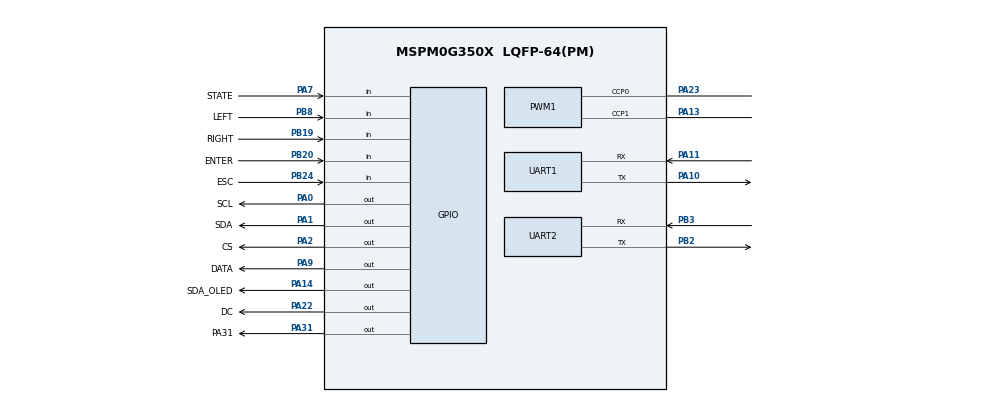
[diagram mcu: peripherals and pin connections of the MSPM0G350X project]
/**
 * @cliArgs --device "MSPM0G350X" --package "LQFP-64(PM)" --part "Default" --product "mspm0_sdk@1.30.00.03"
 * @versions {"tool":"1.19.0+3426"}
 */

/**
 * Import the modules used in this configuration.
 */
const GPIO    = scripting.addModule("/ti/driverlib/GPIO", {}, false);
const GPIO1   = GPIO.addInstance();
const GPIO2   = GPIO.addInstance();
const GPIO3   = GPIO.addInstance();
const GPIO4   = GPIO.addInstance();
const GPIO5   = GPIO.addInstance();
const GPIO6   = GPIO.addInstance();
const PWM     = scripting.addModule("/ti/driverlib/PWM", {}, false);
const PWM1    = PWM.addInstance();
const SYSCTL  = scripting.addModule("/ti/driverlib/SYSCTL");
const SYSTICK = scripting.addModule("/ti/driverlib/SYSTICK");
const UART    = scripting.addModule("/ti/driverlib/UART", {}, false);
const UART1   = UART.addInstance();
const UART2   = UART.addInstance();

/**
 * Write custom configuration values to the imported modules.
 */
GPIO1.$name                          = "GPIO";
GPIO1.port                           = "PORTA";
GPIO1.associatedPins.create(2);
GPIO1.associatedPins[0].$name        = "SCL";
GPIO1.associatedPins[0].initialValue = "SET";
GPIO1.associatedPins[0].ioStructure  = "OD";
GPIO1.associatedPins[0].assignedPin  = "0";
GPIO1.associatedPins[0].pin.$assign  = "PA0";
GPIO1.associatedPins[1].$name        = "SDA";
GPIO1.associatedPins[1].initialValue = "SET";
GPIO1.associatedPins[1].ioStructure  = "OD";
GPIO1.associatedPins[1].assignedPin  = "1";
GPIO1.associatedPins[1].pin.$assign  = "PA1";

const Board = scripting.addModule("/ti/driverlib/Board", {}, false);

GPIO2.$name                          = "GPIO_OLED";
GPIO2.port                           = "PORTA";
GPIO2.associatedPins.create(5);
GPIO2.associatedPins[0].$name        = "SCL_OLED";
GPIO2.associatedPins[0].initialValue = "SET";
GPIO2.associatedPins[0].assignedPin  = "12";
GPIO2.associatedPins[1].$name        = "SDA_OLED";
GPIO2.associatedPins[1].initialValue = "SET";
GPIO2.associatedPins[1].assignedPin  = "14";
GPIO2.associatedPins[1].pin.$assign  = "PA14";
GPIO2.associatedPins[2].$name        = "RES";
GPIO2.associatedPins[2].initialValue = "SET";
GPIO2.associatedPins[2].assignedPin  = "21";
GPIO2.associatedPins[3].$name        = "DC";
GPIO2.associatedPins[3].initialValue = "SET";
GPIO2.associatedPins[3].assignedPin  = "22";
GPIO2.associatedPins[3].pin.$assign  = "PA22";
GPIO2.associatedPins[4].$name        = "CS";
GPIO2.associatedPins[4].initialValue = "SET";
GPIO2.associatedPins[4].assignedPin  = "02";
GPIO2.associatedPins[4].pin.$assign  = "PA2";

GPIO3.port                           = "PORTA";
GPIO3.$name                          = "DHT11";
GPIO3.associatedPins[0].$name        = "DATA";
GPIO3.associatedPins[0].initialValue = "SET";
GPIO3.associatedPins[0].ioStructure  = "HS";
GPIO3.associatedPins[0].assignedPin  = "9";
GPIO3.associatedPins[0].pin.$assign  = "PA9";

GPIO4.$name                         = "GPIO_HC_05";
GPIO4.port                          = "PORTA";
GPIO4.associatedPins[0].$name       = "STATE";
GPIO4.associatedPins[0].direction   = "INPUT";
GPIO4.associatedPins[0].assignedPin = "7";
GPIO4.associatedPins[0].pin.$assign = "PA7";

GPIO5.$name                              = "GPIO_KEY";
GPIO5.port                               = "PORTB";
GPIO5.associatedPins.create(4);
GPIO5.associatedPins[0].$name            = "LEFT";
GPIO5.associatedPins[0].direction        = "INPUT";
GPIO5.associatedPins[0].internalResistor = "PULL_DOWN";
GPIO5.associatedPins[0].pin.$assign      = "PB8";
GPIO5.associatedPins[1].$name            = "RIGHT";
GPIO5.associatedPins[1].direction        = "INPUT";
GPIO5.associatedPins[1].internalResistor = "PULL_DOWN";
GPIO5.associatedPins[1].pin.$assign      = "PB19";
GPIO5.associatedPins[2].$name            = "ENTER";
GPIO5.associatedPins[2].direction        = "INPUT";
GPIO5.associatedPins[2].internalResistor = "PULL_DOWN";
GPIO5.associatedPins[2].pin.$assign      = "PB20";
GPIO5.associatedPins[3].$name            = "ESC";
GPIO5.associatedPins[3].direction        = "INPUT";
GPIO5.associatedPins[3].internalResistor = "PULL_DOWN";
GPIO5.associatedPins[3].pin.$assign      = "PB24";

GPIO6.$name                         = "GPIO_LED";
GPIO6.associatedPins[0].assignedPin = "31";
GPIO6.associatedPins[0].$name       = "PA31";
GPIO6.associatedPins[0].pin.$assign = "PA31";

PWM1.$name                              = "PWM_BUZZER";
PWM1.timerCount                         = 5000;
PWM1.clockDivider                       = 8;
PWM1.peripheral.$assign                 = "TIMG0";
PWM1.peripheral.ccp0Pin.$assign         = "PA23";
PWM1.peripheral.ccp1Pin.$assign         = "PA13";
PWM1.PWM_CHANNEL_0.$name                = "ti_driverlib_pwm_PWMTimerCC0";
PWM1.PWM_CHANNEL_0.ccValue              = 2500;
PWM1.PWM_CHANNEL_1.$name                = "ti_driverlib_pwm_PWMTimerCC1";
PWM1.PWM_CHANNEL_1.ccValue              = 2500;
PWM1.ccp0PinConfig.direction            = scripting.forceWrite("OUTPUT");
PWM1.ccp0PinConfig.hideOutputInversion  = scripting.forceWrite(false);
PWM1.ccp0PinConfig.onlyInternalResistor = scripting.forceWrite(false);
PWM1.ccp0PinConfig.passedPeripheralType = scripting.forceWrite("Digital");
PWM1.ccp0PinConfig.$name                = "ti_driverlib_gpio_GPIOPinGeneric4";
PWM1.ccp1PinConfig.direction            = scripting.forceWrite("OUTPUT");
PWM1.ccp1PinConfig.hideOutputInversion  = scripting.forceWrite(false);
PWM1.ccp1PinConfig.onlyInternalResistor = scripting.forceWrite(false);
PWM1.ccp1PinConfig.passedPeripheralType = scripting.forceWrite("Digital");
PWM1.ccp1PinConfig.$name                = "ti_driverlib_gpio_GPIOPinGeneric5";

SYSCTL.forceDefaultClkConfig = true;
SYSCTL.clockTreeEn           = true;

SYSTICK.periodEnable  = true;
SYSTICK.period        = 32;
SYSTICK.systickEnable = true;

UART1.$name                    = "UART_0";
UART1.enabledInterrupts        = ["RX"];
UART1.peripheral.$assign       = "UART0";
UART1.peripheral.rxPin.$assign = "PA11";
UART1.peripheral.txPin.$assign = "PA10";
UART1.txPinConfig.$name        = "ti_driverlib_gpio_GPIOPinGeneric0";
UART1.rxPinConfig.$name        = "ti_driverlib_gpio_GPIOPinGeneric1";

UART2.enabledInterrupts                = ["RX"];
UART2.$name                            = "UART_HC_05";
UART2.peripheral.$assign               = "UART3";
UART2.peripheral.rxPin.$assign         = "PB3";
UART2.peripheral.txPin.$assign         = "PB2";
UART2.txPinConfig.direction            = scripting.forceWrite("OUTPUT");
UART2.txPinConfig.hideOutputInversion  = scripting.forceWrite(false);
UART2.txPinConfig.onlyInternalResistor = scripting.forceWrite(false);
UART2.txPinConfig.passedPeripheralType = scripting.forceWrite("Digital");
UART2.txPinConfig.$name                = "ti_driverlib_gpio_GPIOPinGeneric2";
UART2.rxPinConfig.hideOutputInversion  = scripting.forceWrite(false);
UART2.rxPinConfig.onlyInternalResistor = scripting.forceWrite(false);
UART2.rxPinConfig.passedPeripheralType = scripting.forceWrite("Digital");
UART2.rxPinConfig.$name                = "ti_driverlib_gpio_GPIOPinGeneric3";

/**
 * Pinmux solution for unlocked pins/peripherals. This ensures that minor changes to the automatic solver in a future
 * version of the tool will not impact the pinmux you originally saw.  These lines can be completely deleted in order to
 * re-solve from scratch.
 */
Board.peripheral.$suggestSolution            = "DEBUGSS";
Board.peripheral.swclkPin.$suggestSolution   = "PA20";
Board.peripheral.swdioPin.$suggestSolution   = "PA19";
GPIO2.associatedPins[0].pin.$suggestSolution = "PA12";
GPIO2.associatedPins[2].pin.$suggestSolution = "PA21";
